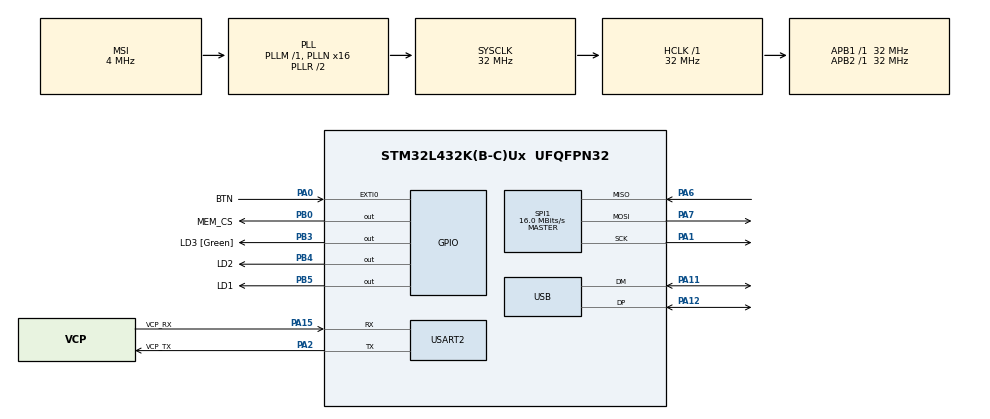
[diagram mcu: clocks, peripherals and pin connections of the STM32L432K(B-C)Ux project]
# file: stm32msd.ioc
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Mcu.Family=STM32L4
Mcu.Name=STM32L432K(B-C)Ux
Mcu.Package=UFQFPN32
NVIC.EXTI0_IRQn=true\:0\:0\:false\:false\:true\:true
NVIC.PriorityGroup=NVIC_PRIORITYGROUP_4
NVIC.USB_IRQn=true\:0\:0\:false\:false\:true\:false
PA0.GPIO_Label=BTN
PA0.GPIO_ModeDefaultEXTI=GPIO_MODE_IT_FALLING
PA0.GPIO_PuPd=GPIO_PULLUP
PA0.Signal=GPXTI0
PA1.Mode=Full_Duplex_Master
PA1.Signal=SPI1_SCK
PA11.Mode=Device
PA11.Signal=USB_DM
PA12.Mode=Device
PA12.Signal=USB_DP
PA13\ (JTMS-SWDIO).GPIO_Label=SWDIO
PA13\ (JTMS-SWDIO).Mode=Serial_Wire
PA13\ (JTMS-SWDIO).Signal=SYS_JTMS-SWDIO
PA14\ (JTCK-SWCLK).GPIO_Label=SWCLK
PA14\ (JTCK-SWCLK).Mode=Serial_Wire
PA14\ (JTCK-SWCLK).Signal=SYS_JTCK-SWCLK
PA15\ (JTDI).GPIO_Label=VCP_RX
PA15\ (JTDI).Mode=Asynchronous
PA15\ (JTDI).Signal=USART2_RX
PA2.GPIO_Label=VCP_TX
PA2.Mode=Asynchronous
PA2.Signal=USART2_TX
PA6.Mode=Full_Duplex_Master
PA6.Signal=SPI1_MISO
PA7.Mode=Full_Duplex_Master
PA7.Signal=SPI1_MOSI
PB0.GPIO_Label=MEM_CS
PB0.GPIO_Speed=GPIO_SPEED_FREQ_HIGH
PB0.PinState=GPIO_PIN_SET
PB0.Signal=GPIO_Output
PB3\ (JTDO-TRACESWO).GPIO_Label=LD3 [Green]
PB3\ (JTDO-TRACESWO).Signal=GPIO_Output
PB4\ (NJTRST).GPIO_Label=LD2
PB4\ (NJTRST).Signal=GPIO_Output
PB5.GPIO_Label=LD1
PB5.Signal=GPIO_Output
PC14-OSC32_IN\ (PC14).Mode=LSE-External-Oscillator
PC14-OSC32_IN\ (PC14).Signal=RCC_OSC32_IN
PC15-OSC32_OUT\ (PC15).Mode=LSE-External-Oscillator
PC15-OSC32_OUT\ (PC15).Signal=RCC_OSC32_OUT
ProjectManager.HeapSize=0x200
ProjectManager.StackSize=0x400
ProjectManager.TargetToolchain=Makefile
RCC.ADCFreq_Value=48000000
RCC.AHBFreq_Value=32000000
RCC.APB1Freq_Value=32000000
RCC.APB1TimFreq_Value=32000000
RCC.APB2Freq_Value=32000000
RCC.APB2TimFreq_Value=32000000
RCC.CK48CLockSelection=RCC_USBCLKSOURCE_HSI48
RCC.CortexFreq_Value=32000000
RCC.HCLKFreq_Value=32000000
RCC.HSE_VALUE=8000000
RCC.HSI16_VALUE=16000000
RCC.HSI48_VALUE=48000000
RCC.HSI_VALUE=16000000
RCC.MSI_VALUE=4000000
RCC.PLLMUL=RCC_PLLMUL_4
RCC.PLLN=16
RCC.PLLSAI1N=24
RCC.SYSCLKFreq_VALUE=32000000
RCC.SYSCLKSource=RCC_SYSCLKSOURCE_PLLCLK
RCC.USBFreq_Value=48000000
RCC.VCOOutputFreq_Value=64000000
SPI1.BaudRatePrescaler=SPI_BAUDRATEPRESCALER_2
SPI1.CalculateBaudRate=16.0 MBits/s
SPI1.DataSize=SPI_DATASIZE_8BIT
SPI1.Direction=SPI_DIRECTION_2LINES
SPI1.Mode=SPI_MODE_MASTER
SPI1.NSSPMode=SPI_NSS_PULSE_DISABLE
SPI1.VirtualType=VM_MASTER
TIM6.Period=1000
TIM6.TIM_MasterOutputTrigger=TIM_TRGO_UPDATE
USART2.VirtualMode-Asynchronous=VM_ASYNC
USB_DEVICE.CLASS_NAME_FS=MSC
USB_DEVICE.MSC_MEDIA_PACKET=4096
USB_DEVICE.VirtualMode=Msc
USB_DEVICE.VirtualModeFS=Msc_FS
VP_TIM6_VS_ClockSourceINT.Mode=Enable_Timer
VP_USB_DEVICE_VS_USB_DEVICE_MSC_FS.Mode=MSC_FS
board=NUCLEO-L432KC

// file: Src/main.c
/**
  ******************************************************************************
  * @file           : main.c
  * @brief          : Main program body
  ******************************************************************************
  * This notice applies to any and all portions of this file
  * that are not between comment pairs USER CODE BEGIN and
  * USER CODE END. Other portions of this file, whether
  * inserted by the user or by software development tools
  * are owned by their respective copyright owners.
  *
  * Copyright (c) 2018 STMicroelectronics International N.V.
  * All rights reserved.
  *
  * Redistribution and use in source and binary forms, with or without
  * modification, are permitted, provided that the following conditions are met:
  *
  * 1. Redistribution of source code must retain the above copyright notice,
  *    this list of conditions and the following disclaimer.
  * 2. Redistributions in binary form must reproduce the above copyright notice,
  *    this list of conditions and the following disclaimer in the documentation
  *    and/or other materials provided with the distribution.
  * 3. Neither the name of STMicroelectronics nor the names of other
  *    contributors to this software may be used to endorse or promote products
  *    derived from this software without specific written permission.
  * 4. This software, including modifications and/or derivative works of this
  *    software, must execute solely and exclusively on microcontroller or
  *    microprocessor devices manufactured by or for STMicroelectronics.
  * 5. Redistribution and use of this software other than as permitted under
  *    this license is void and will automatically terminate your rights under
  *    this license.
  *
  * THIS SOFTWARE IS PROVIDED BY STMICROELECTRONICS AND CONTRIBUTORS "AS IS"
  * AND ANY EXPRESS, IMPLIED OR STATUTORY WARRANTIES, INCLUDING, BUT NOT
  * LIMITED TO, THE IMPLIED WARRANTIES OF MERCHANTABILITY, FITNESS FOR A
  * PARTICULAR PURPOSE AND NON-INFRINGEMENT OF THIRD PARTY INTELLECTUAL PROPERTY
  * RIGHTS ARE DISCLAIMED TO THE FULLEST EXTENT PERMITTED BY LAW. IN NO EVENT
  * SHALL STMICROELECTRONICS OR CONTRIBUTORS BE LIABLE FOR ANY DIRECT, INDIRECT,
  * INCIDENTAL, SPECIAL, EXEMPLARY, OR CONSEQUENTIAL DAMAGES (INCLUDING, BUT NOT
  * LIMITED TO, PROCUREMENT OF SUBSTITUTE GOODS OR SERVICES; LOSS OF USE, DATA,
  * OR PROFITS; OR BUSINESS INTERRUPTION) HOWEVER CAUSED AND ON ANY THEORY OF
  * LIABILITY, WHETHER IN CONTRACT, STRICT LIABILITY, OR TORT (INCLUDING
  * NEGLIGENCE OR OTHERWISE) ARISING IN ANY WAY OUT OF THE USE OF THIS SOFTWARE,
  * EVEN IF ADVISED OF THE POSSIBILITY OF SUCH DAMAGE.
  *
  ******************************************************************************
  */
#include "main.h"
#include "stm32l4xx_hal.h"
#include "usb_device.h"

/* USER CODE BEGIN Includes */
#include "board.h"
#include "SFlash.h"
/* USER CODE END Includes */

SPI_HandleTypeDef hspi1;

TIM_HandleTypeDef htim6;

UART_HandleTypeDef huart2;

/* USER CODE BEGIN PV */
/* Private variables ---------------------------------------------------------*/

/* USER CODE END PV */

void SystemClock_Config(void);
static void MX_GPIO_Init(void);
static void MX_USART2_UART_Init(void);
static void MX_SPI1_Init(void);
static void MX_TIM6_Init(void);

/* USER CODE BEGIN PFP */
/* Private function prototypes -----------------------------------------------*/
void System_Init(void);
/* USER CODE END PFP */

int main(void)
{

  /* MCU Configuration----------------------------------------------------------*/

  /* Reset of all peripherals, Initializes the Flash interface and the Systick. */
  HAL_Init();

  /* Configure the system clock */
  SystemClock_Config();

  /* Initialize all configured peripherals */
  MX_GPIO_Init();
  MX_USART2_UART_Init();
  MX_SPI1_Init();
  MX_USB_DEVICE_Init();
  MX_TIM6_Init();
  /* USER CODE BEGIN 2 */
	System_Init();
  /* USER CODE END 2 */

  /* Infinite loop */
	while (1)
	{

	}

}

void SystemClock_Config(void)
{

  RCC_OscInitTypeDef RCC_OscInitStruct;
  RCC_ClkInitTypeDef RCC_ClkInitStruct;
  RCC_PeriphCLKInitTypeDef PeriphClkInit;

    /**Configure LSE Drive Capability
    */
  HAL_PWR_EnableBkUpAccess();

  __HAL_RCC_LSEDRIVE_CONFIG(RCC_LSEDRIVE_LOW);

    /**Initializes the CPU, AHB and APB busses clocks
    */
  RCC_OscInitStruct.OscillatorType = RCC_OSCILLATORTYPE_HSI48|RCC_OSCILLATORTYPE_LSE
                              |RCC_OSCILLATORTYPE_MSI;
  RCC_OscInitStruct.LSEState = RCC_LSE_ON;
  RCC_OscInitStruct.HSI48State = RCC_HSI48_ON;
  RCC_OscInitStruct.MSIState = RCC_MSI_ON;
  RCC_OscInitStruct.MSICalibrationValue = 0;
  RCC_OscInitStruct.MSIClockRange = RCC_MSIRANGE_6;
  RCC_OscInitStruct.PLL.PLLState = RCC_PLL_ON;
  RCC_OscInitStruct.PLL.PLLSource = RCC_PLLSOURCE_MSI;
  RCC_OscInitStruct.PLL.PLLM = 1;
  RCC_OscInitStruct.PLL.PLLN = 16;
  RCC_OscInitStruct.PLL.PLLP = RCC_PLLP_DIV7;
  RCC_OscInitStruct.PLL.PLLQ = RCC_PLLQ_DIV2;
  RCC_OscInitStruct.PLL.PLLR = RCC_PLLR_DIV2;
  if (HAL_RCC_OscConfig(&RCC_OscInitStruct) != HAL_OK)
  {
    _Error_Handler(__FILE__, __LINE__);
  }

    /**Initializes the CPU, AHB and APB busses clocks
    */
  RCC_ClkInitStruct.ClockType = RCC_CLOCKTYPE_HCLK|RCC_CLOCKTYPE_SYSCLK
                              |RCC_CLOCKTYPE_PCLK1|RCC_CLOCKTYPE_PCLK2;
  RCC_ClkInitStruct.SYSCLKSource = RCC_SYSCLKSOURCE_PLLCLK;
  RCC_ClkInitStruct.AHBCLKDivider = RCC_SYSCLK_DIV1;
  RCC_ClkInitStruct.APB1CLKDivider = RCC_HCLK_DIV1;
  RCC_ClkInitStruct.APB2CLKDivider = RCC_HCLK_DIV1;

  if (HAL_RCC_ClockConfig(&RCC_ClkInitStruct, FLASH_LATENCY_1) != HAL_OK)
  {
    _Error_Handler(__FILE__, __LINE__);
  }

  PeriphClkInit.PeriphClockSelection = RCC_PERIPHCLK_USART2|RCC_PERIPHCLK_USB;
  PeriphClkInit.Usart2ClockSelection = RCC_USART2CLKSOURCE_PCLK1;
  PeriphClkInit.UsbClockSelection = RCC_USBCLKSOURCE_HSI48;
  if (HAL_RCCEx_PeriphCLKConfig(&PeriphClkInit) != HAL_OK)
  {
    _Error_Handler(__FILE__, __LINE__);
  }

    /**Configure the main internal regulator output voltage
    */
  if (HAL_PWREx_ControlVoltageScaling(PWR_REGULATOR_VOLTAGE_SCALE1) != HAL_OK)
  {
    _Error_Handler(__FILE__, __LINE__);
  }

    /**Configure the Systick interrupt time
    */
  HAL_SYSTICK_Config(HAL_RCC_GetHCLKFreq()/1000);

    /**Configure the Systick
    */
  HAL_SYSTICK_CLKSourceConfig(SYSTICK_CLKSOURCE_HCLK);

    /**Enable MSI Auto calibration
    */
  HAL_RCCEx_EnableMSIPLLMode();

  /* SysTick_IRQn interrupt configuration */
  HAL_NVIC_SetPriority(SysTick_IRQn, 0, 0);
}

/* SPI1 init function */
static void MX_SPI1_Init(void)
{

  /* SPI1 parameter configuration*/
  hspi1.Instance = SPI1;
  hspi1.Init.Mode = SPI_MODE_MASTER;
  hspi1.Init.Direction = SPI_DIRECTION_2LINES;
  hspi1.Init.DataSize = SPI_DATASIZE_8BIT;
  hspi1.Init.CLKPolarity = SPI_POLARITY_LOW;
  hspi1.Init.CLKPhase = SPI_PHASE_1EDGE;
  hspi1.Init.NSS = SPI_NSS_SOFT;
  hspi1.Init.BaudRatePrescaler = SPI_BAUDRATEPRESCALER_2;
  hspi1.Init.FirstBit = SPI_FIRSTBIT_MSB;
  hspi1.Init.TIMode = SPI_TIMODE_DISABLE;
  hspi1.Init.CRCCalculation = SPI_CRCCALCULATION_DISABLE;
  hspi1.Init.CRCPolynomial = 7;
  hspi1.Init.CRCLength = SPI_CRC_LENGTH_DATASIZE;
  hspi1.Init.NSSPMode = SPI_NSS_PULSE_DISABLE;
  if (HAL_SPI_Init(&hspi1) != HAL_OK)
  {
    _Error_Handler(__FILE__, __LINE__);
  }

}

/* TIM6 init function */
static void MX_TIM6_Init(void)
{

  TIM_MasterConfigTypeDef sMasterConfig;

  htim6.Instance = TIM6;
  htim6.Init.Prescaler = 0;
  htim6.Init.CounterMode = TIM_COUNTERMODE_UP;
  htim6.Init.Period = 1000;
  htim6.Init.AutoReloadPreload = TIM_AUTORELOAD_PRELOAD_DISABLE;
  if (HAL_TIM_Base_Init(&htim6) != HAL_OK)
  {
    _Error_Handler(__FILE__, __LINE__);
  }

  sMasterConfig.MasterOutputTrigger = TIM_TRGO_UPDATE;
  sMasterConfig.MasterSlaveMode = TIM_MASTERSLAVEMODE_DISABLE;
  if (HAL_TIMEx_MasterConfigSynchronization(&htim6, &sMasterConfig) != HAL_OK)
  {
    _Error_Handler(__FILE__, __LINE__);
  }

}

/* USART2 init function */
static void MX_USART2_UART_Init(void)
{

  huart2.Instance = USART2;
  huart2.Init.BaudRate = 115200;
  huart2.Init.WordLength = UART_WORDLENGTH_8B;
  huart2.Init.StopBits = UART_STOPBITS_1;
  huart2.Init.Parity = UART_PARITY_NONE;
  huart2.Init.Mode = UART_MODE_TX_RX;
  huart2.Init.HwFlowCtl = UART_HWCONTROL_NONE;
  huart2.Init.OverSampling = UART_OVERSAMPLING_16;
  huart2.Init.OneBitSampling = UART_ONE_BIT_SAMPLE_DISABLE;
  huart2.AdvancedInit.AdvFeatureInit = UART_ADVFEATURE_NO_INIT;
  if (HAL_UART_Init(&huart2) != HAL_OK)
  {
    _Error_Handler(__FILE__, __LINE__);
  }

}

/** Configure pins as
        * Analog
        * Input
        * Output
        * EVENT_OUT
        * EXTI
*/
static void MX_GPIO_Init(void)
{

  GPIO_InitTypeDef GPIO_InitStruct;

  /* GPIO Ports Clock Enable */
  __HAL_RCC_GPIOC_CLK_ENABLE();
  __HAL_RCC_GPIOA_CLK_ENABLE();
  __HAL_RCC_GPIOB_CLK_ENABLE();

  /*Configure GPIO pin Output Level */
  HAL_GPIO_WritePin(MEM_CS_GPIO_Port, MEM_CS_Pin, GPIO_PIN_SET);

  /*Configure GPIO pin Output Level */
  HAL_GPIO_WritePin(GPIOB, LD3_Pin|LD2_Pin|LD1_Pin, GPIO_PIN_RESET);

  /*Configure GPIO pin : BTN_Pin */
  GPIO_InitStruct.Pin = BTN_Pin;
  GPIO_InitStruct.Mode = GPIO_MODE_IT_FALLING;
  GPIO_InitStruct.Pull = GPIO_PULLUP;
  HAL_GPIO_Init(BTN_GPIO_Port, &GPIO_InitStruct);

  /*Configure GPIO pin : MEM_CS_Pin */
  GPIO_InitStruct.Pin = MEM_CS_Pin;
  GPIO_InitStruct.Mode = GPIO_MODE_OUTPUT_PP;
  GPIO_InitStruct.Pull = GPIO_NOPULL;
  GPIO_InitStruct.Speed = GPIO_SPEED_FREQ_HIGH;
  HAL_GPIO_Init(MEM_CS_GPIO_Port, &GPIO_InitStruct);

  /*Configure GPIO pins : LD3_Pin LD2_Pin LD1_Pin */
  GPIO_InitStruct.Pin = LD3_Pin|LD2_Pin|LD1_Pin;
  GPIO_InitStruct.Mode = GPIO_MODE_OUTPUT_PP;
  GPIO_InitStruct.Pull = GPIO_NOPULL;
  GPIO_InitStruct.Speed = GPIO_SPEED_FREQ_LOW;
  HAL_GPIO_Init(GPIOB, &GPIO_InitStruct);

  /* EXTI interrupt init*/
  HAL_NVIC_SetPriority(EXTI0_IRQn, 0, 0);
  HAL_NVIC_EnableIRQ(EXTI0_IRQn);

}

/* USER CODE BEGIN 4 */
void HAL_SYSTICK_Callback(void)
{
	static unsigned count = 0;

	if((++count) % 1000 == 0)
	{
		LD3_TOGGLE;
	}
}

void System_Init(void)
{
	DbgPrintf("\r\n\r\nSystem Init");

	SFlash_Init(false);

#if UNIT_TEST
	SFlash_UnitTest();
#endif
}
/* USER CODE END 4 */

void _Error_Handler(char *file, int line)
{
	while(1)
	{
	}
}

/************************ (C) COPYRIGHT STMicroelectronics *****END OF FILE****/
